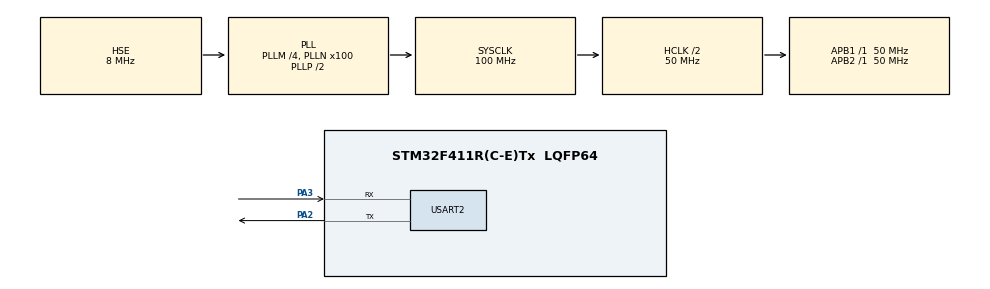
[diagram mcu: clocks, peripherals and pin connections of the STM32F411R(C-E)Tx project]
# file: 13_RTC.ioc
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Mcu.Family=STM32F4
Mcu.Name=STM32F411R(C-E)Tx
Mcu.Package=LQFP64
NVIC.PriorityGroup=NVIC_PRIORITYGROUP_4
NVIC.USART2_IRQn=true\:0\:0\:false\:false\:true\:true\:true\:true
PA2.Mode=Asynchronous
PA2.Signal=USART2_TX
PA3.Mode=Asynchronous
PA3.Signal=USART2_RX
PH0\ -\ OSC_IN.Mode=HSE-External-Oscillator
PH0\ -\ OSC_IN.Signal=RCC_OSC_IN
PH1\ -\ OSC_OUT.Mode=HSE-External-Oscillator
PH1\ -\ OSC_OUT.Signal=RCC_OSC_OUT
ProjectManager.HeapSize=0x200
ProjectManager.StackSize=0x400
ProjectManager.TargetToolchain=STM32CubeIDE
RCC.48MHZClocksFreq_Value=50000000
RCC.AHBCLKDivider=RCC_SYSCLK_DIV2
RCC.AHBFreq_Value=50000000
RCC.APB1Freq_Value=50000000
RCC.APB1TimFreq_Value=50000000
RCC.APB2Freq_Value=50000000
RCC.APB2TimFreq_Value=50000000
RCC.CortexFreq_Value=50000000
RCC.HCLKFreq_Value=50000000
RCC.HSE_VALUE=8000000
RCC.HSI_VALUE=16000000
RCC.LSE_VALUE=32768
RCC.PLLM=4
RCC.PLLN=100
RCC.PLLSourceVirtual=RCC_PLLSOURCE_HSE
RCC.SYSCLKFreq_VALUE=100000000
RCC.SYSCLKSource=RCC_SYSCLKSOURCE_PLLCLK
RCC.VCOOutputFreq_Value=200000000
USART2.VirtualMode=VM_ASYNC
VP_RTC_VS_RTC_Activate.Mode=RTC_Enabled
VP_RTC_VS_RTC_Calendar.Mode=RTC_Calendar
board=custom

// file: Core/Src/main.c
/* USER CODE BEGIN Header */
/**
  ******************************************************************************
  * @file           : main.c
  * @brief          : Main program body
  ******************************************************************************
  * @attention
  *
  * Copyright (c) 2025 STMicroelectronics.
  * All rights reserved.
  *
  * This software is licensed under terms that can be found in the LICENSE file
  * in the root directory of this software component.
  * If no LICENSE file comes with this software, it is provided AS-IS.
  *
  ******************************************************************************
  */
/* USER CODE END Header */
#include "main.h"
#include "rtc.h"
#include "usart.h"
#include "gpio.h"

/* USER CODE BEGIN Includes */

#include "stdio.h"
#include "string.h"

/* USER CODE END Includes */

/* USER CODE BEGIN PD */

#define BCD_TO_DEC(val) (((val>>4)*10)+(val&0x0F)) //10의자리는 4bit shift한다음 x10, 1의자리는 그냥 사용
#define DEC_TO_BCD(val)	(((val/10)<<4|(val%10))) //

/* USER CODE END PD */

/* USER CODE BEGIN PV */

RTC_TimeTypeDef rtcTime;
RTC_DateTypeDef rtcDate;

char temp[50];

uint8_t rxData;
uint8_t	buffIndex=0;
uint8_t buff[30];

/* USER CODE END PV */

void SystemClock_Config(void);

int main(void)
{

  /* MCU Configuration--------------------------------------------------------*/

  /* Reset of all peripherals, Initializes the Flash interface and the Systick. */
  HAL_Init();

  /* Configure the system clock */
  SystemClock_Config();

  /* Initialize all configured peripherals */
  MX_GPIO_Init();
  MX_RTC_Init();
  MX_USART2_UART_Init();
  /* USER CODE BEGIN 2 */

  HAL_UART_Receive_IT(&huart2, &rxData, 1);

  /* USER CODE END 2 */

  /* Infinite loop */
  /* USER CODE BEGIN WHILE */
  while (1)
  {
	  HAL_RTC_GetTime(&hrtc,&rtcTime,RTC_FORMAT_BCD);
	  HAL_RTC_GetDate(&hrtc,&rtcDate,RTC_FORMAT_BCD);

	  sprintf(temp, "\r\n20%02x-%02x-%02x %02x:%02x:%02x",
			  	  rtcDate.Year, rtcDate.Month, rtcDate.Date,
				  rtcTime.Hours, rtcTime.Minutes, rtcTime.Seconds);

	  HAL_UART_Transmit(&huart2, (uint8_t *)temp, strlen(temp), 10);
	  HAL_Delay(1000);

    /* USER CODE END WHILE */

  }
}

void SystemClock_Config(void)
{
  RCC_OscInitTypeDef RCC_OscInitStruct = {0};
  RCC_ClkInitTypeDef RCC_ClkInitStruct = {0};

  /** Configure the main internal regulator output voltage
  */
  __HAL_RCC_PWR_CLK_ENABLE();
  __HAL_PWR_VOLTAGESCALING_CONFIG(PWR_REGULATOR_VOLTAGE_SCALE1);

  /** Initializes the RCC Oscillators according to the specified parameters
  * in the RCC_OscInitTypeDef structure.
  */
  RCC_OscInitStruct.OscillatorType = RCC_OSCILLATORTYPE_LSI|RCC_OSCILLATORTYPE_HSE;
  RCC_OscInitStruct.HSEState = RCC_HSE_ON;
  RCC_OscInitStruct.LSIState = RCC_LSI_ON;
  RCC_OscInitStruct.PLL.PLLState = RCC_PLL_ON;
  RCC_OscInitStruct.PLL.PLLSource = RCC_PLLSOURCE_HSE;
  RCC_OscInitStruct.PLL.PLLM = 4;
  RCC_OscInitStruct.PLL.PLLN = 100;
  RCC_OscInitStruct.PLL.PLLP = RCC_PLLP_DIV2;
  RCC_OscInitStruct.PLL.PLLQ = 4;
  if (HAL_RCC_OscConfig(&RCC_OscInitStruct) != HAL_OK)
  {
    Error_Handler();
  }

  /** Initializes the CPU, AHB and APB buses clocks
  */
  RCC_ClkInitStruct.ClockType = RCC_CLOCKTYPE_HCLK|RCC_CLOCKTYPE_SYSCLK
                              |RCC_CLOCKTYPE_PCLK1|RCC_CLOCKTYPE_PCLK2;
  RCC_ClkInitStruct.SYSCLKSource = RCC_SYSCLKSOURCE_PLLCLK;
  RCC_ClkInitStruct.AHBCLKDivider = RCC_SYSCLK_DIV2;
  RCC_ClkInitStruct.APB1CLKDivider = RCC_HCLK_DIV1;
  RCC_ClkInitStruct.APB2CLKDivider = RCC_HCLK_DIV1;

  if (HAL_RCC_ClockConfig(&RCC_ClkInitStruct, FLASH_LATENCY_1) != HAL_OK)
  {
    Error_Handler();
  }
}

/* USER CODE BEGIN 4 */

// date setup : uart terminal에 setDate251028 입력
// Time setup : uart terminal에 setTime100125 입력

void HAL_UART_RxCpltCallback(UART_HandleTypeDef *huart)
{
	  if(huart->Instance==USART2)
	  {
		  if(rxData == '\n') //수신된 데이터가 \n이면
		  {
			  buff[buffIndex] = 0;	// null문자를 추가하여 문자열로 만듦
			  char *ptr;

			  if((ptr=strstr((char*)buff, "setTime")) != NULL)
			  {		// buff 안에 "setTime"이라는 문자열이 포함되어 있으면 (null값이아니면)
				  	// 그 위치의 주소를 ptr(포인터)에 저장하고, 아래 구문을 실행
				  rtcTime.Hours = ((*(ptr+7) - '0') << 4)+(*(ptr+8)-'0');		// setTime'10'0125 을 읽어 hour 설정
				  rtcTime.Minutes = ((*(ptr+9) - '0') << 4)+(*(ptr+10)-'0');	// setTime10'01'25 을 읽어 minute 설정
				  rtcTime.Seconds = ((*(ptr+11) - '0') << 4)+(*(ptr+12)-'0');	// setTime1001'25' 을 읽어 seconds 설정

				  HAL_RTC_SetTime(&hrtc, &rtcTime, RTC_FORMAT_BCD);
			  }
			  else if((ptr=strstr((char*)buff, "setDate")) != NULL)
			  {		// buff 안에 "setDate"이라는 문자열이 포함되어 있으면 (null값이아니면)
				  	// 그 위치의 주소를 ptr(포인터)에 저장하고, 아래 구문을 실행
				  rtcDate.Year = ((*(ptr+7) - '0') << 4)+(*(ptr+8)-'0');		// setDate'25'1028 을 읽어 Year 설정
				  rtcDate.Month = ((*(ptr+9) - '0') << 4)+(*(ptr+10)-'0');	// setDate25'10'28 을 읽어 Month 설정
				  rtcDate.Date = ((*(ptr+11) - '0') << 4)+(*(ptr+12)-'0');	// setDate2510'28' 을 읽어 Date 설정

				  HAL_RTC_SetDate(&hrtc, &rtcDate, RTC_FORMAT_BCD);
			  }
			  buffIndex = 0;
		  }
		  else
		  {
			  //수신된 data가 \n이 아니라면
			  if(buffIndex<30)
					  buff[buffIndex++] = rxData;	//버퍼에 데이터 추가
		  }
		  HAL_UART_Receive_IT(&huart2, &rxData, 1);
	  }

//	  else if(huart->Instance==USART3)	//UART3을 사용할시 추가 코드
//	  {
//		  HAL_UART_Receive_IT(&huart3, &rxData, 1);
//	  }
}

/* USER CODE END 4 */

void Error_Handler(void)
{
  __disable_irq();
  while (1)
  {
  }
}
